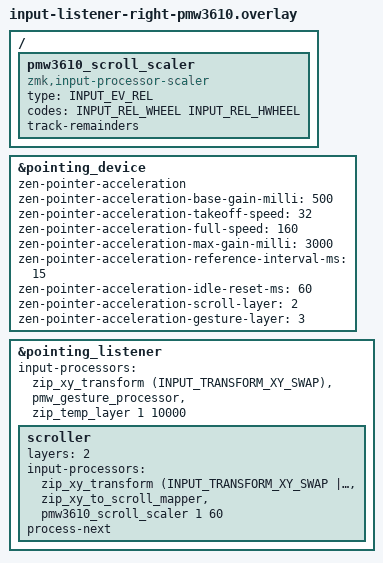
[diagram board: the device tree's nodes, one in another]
#include <dt-bindings/zmk/input_transform.h>

/ {
    pmw3610_scroll_scaler: pmw3610_scroll_scaler {
        compatible = "zmk,input-processor-scaler";
        #input-processor-cells = <2>;
        type = <INPUT_EV_REL>;
        codes = <INPUT_REL_WHEEL INPUT_REL_HWHEEL>;
        track-remainders;
    };
};

/*
 * Apply a continuous same-frame gain curve at the PMW3610 15 ms aggregation
 * point. Low speed is 0.5x (600-CPI-equivalent at raw 1200 CPI). Scroll and
 * Gesture receive bit-exact raw deltas by bypassing acceleration on layers 2/3.
 */
&pointing_device {
    zen-pointer-acceleration;
    zen-pointer-acceleration-base-gain-milli = <500>;
    zen-pointer-acceleration-takeoff-speed = <32>;
    zen-pointer-acceleration-full-speed = <160>;
    zen-pointer-acceleration-max-gain-milli = <3000>;
    zen-pointer-acceleration-reference-interval-ms = <15>;
    zen-pointer-acceleration-idle-reset-ms = <60>;
    zen-pointer-acceleration-scroll-layer = <2>;
    zen-pointer-acceleration-gesture-layer = <3>;
};

&pointing_listener {
    input-processors =
        <&zip_xy_transform (INPUT_TRANSFORM_XY_SWAP)>,
        <&pmw_gesture_processor>,
        <&zip_temp_layer 1 10000>;

    scroller {
        layers = <2>;
        input-processors =
            <&zip_xy_transform (INPUT_TRANSFORM_XY_SWAP | INPUT_TRANSFORM_Y_INVERT)>,
            <&zip_xy_to_scroll_mapper>,
            <&pmw3610_scroll_scaler 1 60>;
        process-next;
    };
};
